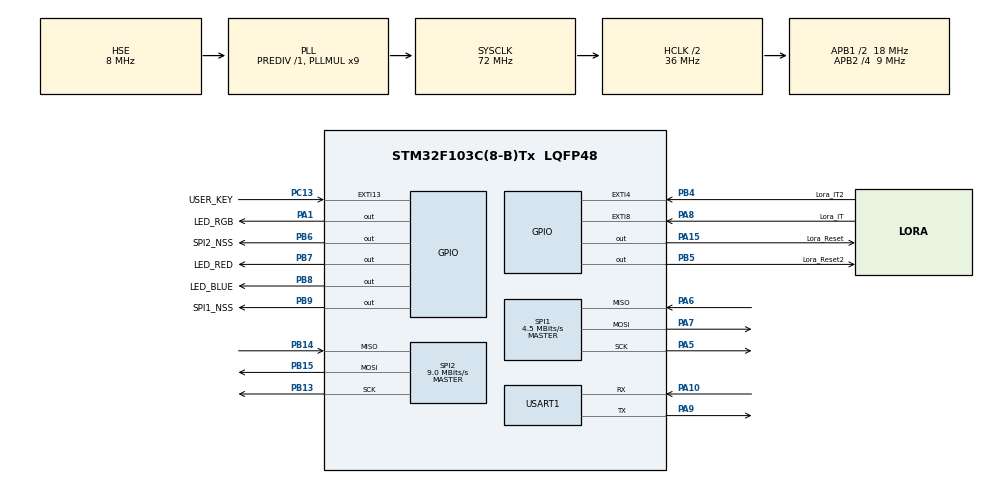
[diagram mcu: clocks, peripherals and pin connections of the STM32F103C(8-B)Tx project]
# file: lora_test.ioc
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Mcu.Family=STM32F1
Mcu.Name=STM32F103C(8-B)Tx
Mcu.Package=LQFP48
NVIC.EXTI15_10_IRQn=true\:0\:0\:false\:false\:true\:true\:true
NVIC.EXTI4_IRQn=true\:0\:0\:false\:false\:true\:true\:true
NVIC.EXTI9_5_IRQn=true\:0\:0\:false\:false\:true\:true\:true
NVIC.PriorityGroup=NVIC_PRIORITYGROUP_4
NVIC.TIM1_UP_IRQn=true\:0\:0\:false\:false\:true\:true\:true
NVIC.USART1_IRQn=true\:0\:0\:false\:false\:true\:true\:true
PA1.GPIO_Label=LED_RGB
PA1.Signal=GPIO_Output
PA10.Mode=Asynchronous
PA10.Signal=USART1_RX
PA13.Mode=Serial_Wire
PA13.Signal=SYS_JTMS-SWDIO
PA14.Mode=Serial_Wire
PA14.Signal=SYS_JTCK-SWCLK
PA15.GPIO_Label=Lora_Reset
PA15.GPIO_PuPd=GPIO_PULLUP
PA15.PinState=GPIO_PIN_SET
PA15.Signal=GPIO_Output
PA5.Mode=Full_Duplex_Master
PA5.Signal=SPI1_SCK
PA6.Mode=Full_Duplex_Master
PA6.Signal=SPI1_MISO
PA7.Mode=Full_Duplex_Master
PA7.Signal=SPI1_MOSI
PA8.GPIO_Label=Lora_IT
PA8.GPIO_PuPd=GPIO_PULLUP
PA8.Signal=GPXTI8
PA9.Mode=Asynchronous
PA9.Signal=USART1_TX
PB13.Mode=Full_Duplex_Master
PB13.Signal=SPI2_SCK
PB14.Mode=Full_Duplex_Master
PB14.Signal=SPI2_MISO
PB15.Mode=Full_Duplex_Master
PB15.Signal=SPI2_MOSI
PB4.GPIO_Label=Lora_IT2
PB4.GPIO_ModeDefaultEXTI=GPIO_MODE_IT_RISING
PB4.GPIO_PuPd=GPIO_PULLDOWN
PB4.Signal=GPXTI4
PB5.GPIO_Label=Lora_Reset2
PB5.GPIO_PuPd=GPIO_PULLUP
PB5.PinState=GPIO_PIN_SET
PB5.Signal=GPIO_Output
PB6.GPIO_Label=SPI2_NSS
PB6.GPIO_PuPd=GPIO_PULLUP
PB6.PinState=GPIO_PIN_SET
PB6.Signal=GPIO_Output
PB7.GPIO_Label=LED_RED
PB7.Signal=GPIO_Output
PB8.GPIO_Label=LED_BLUE
PB8.Signal=GPIO_Output
PB9.GPIO_Label=SPI1_NSS
PB9.GPIO_PuPd=GPIO_PULLUP
PB9.PinState=GPIO_PIN_SET
PB9.Signal=GPIO_Output
PC13-TAMPER-RTC.GPIO_Label=USER_KEY
PC13-TAMPER-RTC.GPIO_ModeDefaultEXTI=GPIO_MODE_IT_FALLING
PC13-TAMPER-RTC.GPIO_PuPd=GPIO_PULLUP
PC13-TAMPER-RTC.Signal=GPXTI13
PC14-OSC32_IN.Mode=LSE-External-Oscillator
PC14-OSC32_IN.Signal=RCC_OSC32_IN
PC15-OSC32_OUT.Mode=LSE-External-Oscillator
PC15-OSC32_OUT.Signal=RCC_OSC32_OUT
PD0-OSC_IN.Mode=HSE-External-Oscillator
PD0-OSC_IN.Signal=RCC_OSC_IN
PD1-OSC_OUT.Mode=HSE-External-Oscillator
PD1-OSC_OUT.Signal=RCC_OSC_OUT
ProjectManager.HeapSize=0x200
ProjectManager.StackSize=0x400
ProjectManager.TargetToolchain=MDK-ARM V5.32
RCC.AHBCLKDivider=RCC_SYSCLK_DIV2
RCC.AHBFreq_Value=36000000
RCC.APB1CLKDivider=RCC_HCLK_DIV2
RCC.APB1Freq_Value=18000000
RCC.APB1TimFreq_Value=36000000
RCC.APB2CLKDivider=RCC_HCLK_DIV4
RCC.APB2Freq_Value=9000000
RCC.APB2TimFreq_Value=18000000
RCC.HCLKFreq_Value=36000000
RCC.PLLMUL=RCC_PLL_MUL9
RCC.PLLSourceVirtual=RCC_PLLSOURCE_HSE
RCC.SYSCLKFreq_VALUE=72000000
RCC.SYSCLKSource=RCC_SYSCLKSOURCE_PLLCLK
RCC.USBFreq_Value=72000000
SPI1.BaudRatePrescaler=SPI_BAUDRATEPRESCALER_2
SPI1.CalculateBaudRate=4.5 MBits/s
SPI1.Direction=SPI_DIRECTION_2LINES
SPI1.Mode=SPI_MODE_MASTER
SPI1.VirtualType=VM_MASTER
SPI2.CalculateBaudRate=9.0 MBits/s
SPI2.Direction=SPI_DIRECTION_2LINES
SPI2.Mode=SPI_MODE_MASTER
SPI2.VirtualType=VM_MASTER
TIM1.AutoReloadPreload=TIM_AUTORELOAD_PRELOAD_ENABLE
TIM1.Period=99
TIM1.Prescaler=319
USART1.VirtualMode=VM_ASYNC
VP_TIM1_VS_ClockSourceINT.Mode=Internal
board=custom

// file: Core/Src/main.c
/* USER CODE BEGIN Header */
/**
  ******************************************************************************
  * @file           : main.c
  * @brief          : Main program body
  ******************************************************************************
  * @attention
  *
  * Copyright (c) 2024 STMicroelectronics.
  * All rights reserved.
  *
  * This software is licensed under terms that can be found in the LICENSE file
  * in the root directory of this software component.
  * If no LICENSE file comes with this software, it is provided AS-IS.
  *
  ******************************************************************************
  */
/* USER CODE END Header */
#include "main.h"
#include "spi.h"
#include "tim.h"
#include "usart.h"
#include "gpio.h"

/* USER CODE BEGIN Includes */
#include "lora.h"
/* USER CODE END Includes */

void SystemClock_Config(void);

int main(void)
{
  /* USER CODE BEGIN 1 */
	static uint8_t txData[32];        // lora间隔500ms向外发送一次测试信息
    static uint16_t  cnt;
	char str[13] = "hello world\r\n";
  /* USER CODE END 1 */

  /* MCU Configuration--------------------------------------------------------*/

  /* Reset of all peripherals, Initializes the Flash interface and the Systick. */
  HAL_Init();

  /* Configure the system clock */
  SystemClock_Config();

  /* Initialize all configured peripherals */
  MX_GPIO_Init();
  MX_SPI1_Init();
  MX_TIM1_Init();
  MX_USART1_UART_Init();
  MX_SPI2_Init();
  /* USER CODE BEGIN 2 */
  HAL_Delay(500);
  Lora_Init( 416, 11, 8);
//  Lora_Init2(416, 11, 8);
	HAL_TIM_Base_Start_IT(&htim1);

	printf("systerm start!\r\n");
	HAL_UART_Transmit(&huart1,(uint8_t*)str,13,0xFFFFFF);
  /* USER CODE END 2 */

  /* Infinite loop */
  /* USER CODE BEGIN WHILE */
  while (1)
  {
	sprintf((char*)txData, "123456789999888777fffyyyzzz%d",cnt++);
    Lora_TxData (txData, sizeof(txData)) ;

    printf("已发送第 %d 次数据,\r\n", cnt);
	HAL_Delay(5000);
    /* USER CODE END WHILE */
  }
}

void SystemClock_Config(void)
{
  RCC_OscInitTypeDef RCC_OscInitStruct = {0};
  RCC_ClkInitTypeDef RCC_ClkInitStruct = {0};

  /** Initializes the RCC Oscillators according to the specified parameters
  * in the RCC_OscInitTypeDef structure.
  */
  RCC_OscInitStruct.OscillatorType = RCC_OSCILLATORTYPE_HSE;
  RCC_OscInitStruct.HSEState = RCC_HSE_ON;
  RCC_OscInitStruct.HSEPredivValue = RCC_HSE_PREDIV_DIV1;
  RCC_OscInitStruct.HSIState = RCC_HSI_ON;
  RCC_OscInitStruct.PLL.PLLState = RCC_PLL_ON;
  RCC_OscInitStruct.PLL.PLLSource = RCC_PLLSOURCE_HSE;
  RCC_OscInitStruct.PLL.PLLMUL = RCC_PLL_MUL9;
  if (HAL_RCC_OscConfig(&RCC_OscInitStruct) != HAL_OK)
  {
    Error_Handler();
  }
  /** Initializes the CPU, AHB and APB buses clocks
  */
  RCC_ClkInitStruct.ClockType = RCC_CLOCKTYPE_HCLK|RCC_CLOCKTYPE_SYSCLK
                              |RCC_CLOCKTYPE_PCLK1|RCC_CLOCKTYPE_PCLK2;
  RCC_ClkInitStruct.SYSCLKSource = RCC_SYSCLKSOURCE_PLLCLK;
  RCC_ClkInitStruct.AHBCLKDivider = RCC_SYSCLK_DIV2;
  RCC_ClkInitStruct.APB1CLKDivider = RCC_HCLK_DIV2;
  RCC_ClkInitStruct.APB2CLKDivider = RCC_HCLK_DIV4;

  if (HAL_RCC_ClockConfig(&RCC_ClkInitStruct, FLASH_LATENCY_2) != HAL_OK)
  {
    Error_Handler();
  }
}

void Error_Handler(void)
{
  __disable_irq();
  while (1)
  {
  }
}
